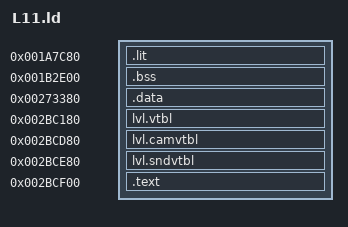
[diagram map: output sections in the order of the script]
/* GENERATED by tools/levels/gen_ld.py going-decompiled/levels/usa/L11/config/L11.yaml -- do not edit; re-run it. */
/* USA v2.00 level program 11: 7 sections at their dests, one PT_LOAD, entry 0x002BCF08,
   program sha1 36b9ba98fdfa868c2283bc5ec1bc9c0b63295a71 (archive form). Built by tools/levels/level_build.sh. */
/* From C (config/L11_c.tsv), cut out of the .text asm and linked at their place:
   func_L11_003417D0 at 0x003417D0, 0x48 bytes, src/func_L11_003417D0.c, s136 -G0
   func_L11_0036A7F8 at 0x0036A7F8, 0x110 bytes, src/func_L11_0036A7F8.c, s136 -G8
   func_L11_003983E0 at 0x003983E0, 0x130 bytes, src/func_L11_003983E0.c, s136 -G8, assembler asm_unit, extra cc1 flags -
   func_L11_003F3178 at 0x003F3178, 0xB0 bytes, src/func_L11_003F3178.c, s136 -G8, assembler asm_unit, extra cc1 flags -
   func_L11_003F4310 at 0x003F4310, 0x34 bytes, src/func_L11_003F4310.c, sdk29 -G0
   func_L11_003F4448 at 0x003F4448, 0x160 bytes, src/func_L11_003F4448.c, s136 -G8, assembler asm_unit, extra cc1 flags -
   func_L11_00414290 at 0x00414290, 0x144 bytes, src/func_L11_00414290.c, s136 -G8
   func_L11_00418AB0 at 0x00418AB0, 0x2F8 bytes, src/func_L11_00418AB0.c, s136 -G8, assembler asm_unit, extra cc1 flags -
   func_L11_00426FA0 at 0x00426FA0, 0x2C4 bytes, src/func_L11_00426FA0.c, s136 -G8, assembler asm_unit, extra cc1 flags -
   func_L11_00427310 at 0x00427310, 0xE4 bytes, src/func_L11_00427310.c, s136 -G0
   func_L11_0042B988 at 0x0042B988, 0x2C4 bytes, src/func_L11_0042B988.c, s136 -G8, assembler asm_unit, extra cc1 flags -
   func_L11_0042BCF8 at 0x0042BCF8, 0xE4 bytes, src/func_L11_0042BCF8.c, s136 -G0
   func_L11_00436338 at 0x00436338, 0x208 bytes, src/func_L11_00436338.c, s136 -G8, assembler asm_unit, extra cc1 flags -
   func_L11_00437B90 at 0x00437B90, 0x414 bytes, src/func_L11_00437B90.c, s136 -G8, assembler asm_unit, extra cc1 flags -
   func_L11_00439600 at 0x00439600, 0xA4 bytes, src/func_L11_00439600.c, s136 -G0
   func_L11_004396A8 at 0x004396A8, 0x40 bytes, src/func_L11_004396A8.c, s136 -G0
   func_L11_0043A758 at 0x0043A758, 0x1B4 bytes, src/func_L11_0043A758.c, s136 -G0
   func_L11_0043AE08 at 0x0043AE08, 0x74 bytes, src/func_L11_0043AE08.c, s136 -G8, assembler asm_unit, extra cc1 flags -
   func_L11_0043B430 at 0x0043B430, 0x16C bytes, src/func_L11_0043B430.c, s136 -G0
   func_L11_0043B5A0 at 0x0043B5A0, 0x18 bytes, src/func_L11_0043B5A0.c, s136 -G0
   func_L11_0043BC38 at 0x0043BC38, 0x228 bytes, src/func_L11_0043BC38.c, s136 -G8, assembler asm_unit, extra cc1 flags -
   func_L11_0043BE60 at 0x0043BE60, 0x5C bytes, src/func_L11_0043BE60.c, s136 -G0
   func_L11_0043C040 at 0x0043C040, 0x10 bytes, src/func_L11_0043C040.c, sdk29 -G0
   func_L11_0043C218 at 0x0043C218, 0x150 bytes, src/func_L11_0043C218.c, s136 -G8, assembler asm_unit, extra cc1 flags -
   func_L11_0043C368 at 0x0043C368, 0x188 bytes, src/func_L11_0043C368.c, s136 -G0
   func_L11_004419B0 at 0x004419B0, 0x5C bytes, src/func_L11_004419B0.c, s136 -G0
   func_L11_00441A88 at 0x00441A88, 0x128 bytes, src/func_L11_00441A88.c, sdk29 -G8
   func_L11_00441FE0 at 0x00441FE0, 0xD4 bytes, src/func_L11_00441FE0.c, s136 -G8
   func_L11_004420B8 at 0x004420B8, 0x108 bytes, src/func_L11_004420B8.c, s136 -G0
   func_L11_004424D0 at 0x004424D0, 0xC bytes, src/func_L11_004424D0.c, sdk29 -G0
   func_L11_004424E0 at 0x004424E0, 0x188 bytes, src/func_L11_004424E0.c, s136 -G0
   func_L11_00442668 at 0x00442668, 0x274 bytes, src/func_L11_00442668.c, s136 -G8, assembler asm_unit, extra cc1 flags -
   func_L11_004428E0 at 0x004428E0, 0x78 bytes, src/func_L11_004428E0.c, s136 -G0
   func_L11_00442A18 at 0x00442A18, 0x188 bytes, src/func_L11_00442A18.c, s136 -G0
   func_L11_00442FF8 at 0x00442FF8, 0x40 bytes, src/func_L11_00442FF8.c, sdk29 -G0
   func_L11_00443038 at 0x00443038, 0x20 bytes, src/func_L11_00443038.c, sdk29 -G0
   func_L11_00443058 at 0x00443058, 0x50 bytes, src/func_L11_00443058.c, sdk29 -G0
   func_L11_004430A8 at 0x004430A8, 0xC bytes, src/func_L11_004430A8.c, sdk29 -G0
   func_L11_004430B8 at 0x004430B8, 0x10C bytes, src/func_L11_004430B8.c, sdk29 -G0
   func_L11_004431C8 at 0x004431C8, 0xBC bytes, src/func_L11_004431C8.c, sdk29 -G0
   func_L11_00443C48 at 0x00443C48, 0x1D0 bytes, src/func_L11_00443C48.c, s136 -G8, assembler asm_unit, extra cc1 flags -
   func_L11_00443E18 at 0x00443E18, 0x148 bytes, src/func_L11_00443E18.c, s136 -G0
   func_L11_00443F60 at 0x00443F60, 0xA4 bytes, src/func_L11_00443F60.c, s136 -G8, assembler asm_unit, extra cc1 flags -
   func_L11_00444BD0 at 0x00444BD0, 0x58 bytes, src/func_L11_00444BD0.c, s136 -G8, assembler asm_unit, extra cc1 flags -
   func_L11_00444CE8 at 0x00444CE8, 0x4A4 bytes, src/func_L11_00444CE8.c, s136 -G8, assembler asm_unit, extra cc1 flags -
   func_L11_00447750 at 0x00447750, 0x88 bytes, src/func_L11_00447750.c, s136 -G0
   func_L11_00447A48 at 0x00447A48, 0x1A0 bytes, src/func_L11_00447A48.c, s136 -G8
   func_L11_00447BE8 at 0x00447BE8, 0x24 bytes, src/func_L11_00447BE8.c, sdk29 -G0
   func_L11_00449ED0 at 0x00449ED0, 0x39C bytes, src/func_L11_00449ED0.c, s136 -G8, assembler asm_unit, extra cc1 flags -
   func_L11_0044A270 at 0x0044A270, 0xC0 bytes, src/func_L11_0044A270.c, s136 -G0
   func_L11_0044A330 at 0x0044A330, 0x8C bytes, src/func_L11_0044A330.c, s136 -G0
   func_L11_0044A4D0 at 0x0044A4D0, 0x1D8 bytes, src/func_L11_0044A4D0.c, s136 -G8, assembler asm_unit, extra cc1 flags -
   func_L11_0044A750 at 0x0044A750, 0xD0 bytes, src/func_L11_0044A750.c, s136 -G8
   func_L11_0044AAC0 at 0x0044AAC0, 0x208 bytes, src/func_L11_0044AAC0.c, s136 -G8, assembler asm_unit, extra cc1 flags -
   func_L11_0044AD58 at 0x0044AD58, 0xC8 bytes, src/func_L11_0044AD58.c, s136 -G8, assembler asm_unit, extra cc1 flags -
   func_L11_0044D7A0 at 0x0044D7A0, 0x384 bytes, src/func_L11_0044D7A0.c, s136 -G8, assembler asm_unit, extra cc1 flags -
   func_L11_00453EA8 at 0x00453EA8, 0x3BC bytes, src/func_L11_00453EA8.c, s136 -G8, assembler asm_unit, extra cc1 flags -
   func_L11_00455F60 at 0x00455F60, 0x5D8 bytes, src/func_L11_00455F60.c, s136 -G8, assembler asm_unit, extra cc1 flags -
   func_L11_00456538 at 0x00456538, 0x80 bytes, src/func_L11_00456538.c, s136 -G0
   func_L11_004565B8 at 0x004565B8, 0x118 bytes, src/func_L11_004565B8.c, s136 -G0
   func_L11_004566D0 at 0x004566D0, 0x160 bytes, src/func_L11_004566D0.c, s136 -G0
   func_L11_00456830 at 0x00456830, 0x13C bytes, src/func_L11_00456830.c, s136 -G0
   func_L11_00457A68 at 0x00457A68, 0x5C bytes, src/func_L11_00457A68.c, s136 -G0
   func_L11_00457DD0 at 0x00457DD0, 0xC0 bytes, src/func_L11_00457DD0.c, s136 -G0
   func_L11_00457F98 at 0x00457F98, 0x94 bytes, src/func_L11_00457F98.c, s136 -G0
   func_L11_00458678 at 0x00458678, 0x280 bytes, src/func_L11_00458678.c, s136 -G0
   func_L11_0045A6F0 at 0x0045A6F0, 0xC8 bytes, src/func_L11_0045A6F0.c, s136 -G8, assembler asm_unit, extra cc1 flags -
   func_L11_0045A840 at 0x0045A840, 0x68 bytes, src/func_L11_0045A840.c, s136 -G0
   func_L11_0045AA10 at 0x0045AA10, 0x38 bytes, src/func_L11_0045AA10.c, s136 -G0
   func_L11_0045B800 at 0x0045B800, 0xFC bytes, src/func_L11_0045B800.c, s136 -G8, assembler asm_unit, extra cc1 flags -
   func_L11_00461AD8 at 0x00461AD8, 0x68 bytes, src/func_L11_00461AD8.c, s136 -G0
*/
OUTPUT_ARCH(mips)
ENTRY(func_L11_002BCF08)
PHDRS
{
    program PT_LOAD;
}
SECTIONS
{
    _gp = 0x001AEFF0;
    .lit 0x001A7C80 : { going-decompiled/build/usa_levels/L11/obj/data/lit/001A7C80.data.o(.data) } :program
    .bss 0x001B2E00 : { going-decompiled/build/usa_levels/L11/obj/data/bss/001B2E00.bss.o(.bss) } :program
    .data 0x00273380 : { going-decompiled/build/usa_levels/L11/obj/data/data/00273380.data.o(.data) } :program
    lvl.vtbl 0x002BC180 : { going-decompiled/build/usa_levels/L11/obj/data/lvl.vtbl/002BC180.data.o(.data) } :program
    lvl.camvtbl 0x002BCD80 : { going-decompiled/build/usa_levels/L11/obj/data/lvl.camvtbl/002BCD80.data.o(.data) } :program
    lvl.sndvtbl 0x002BCE80 : { going-decompiled/build/usa_levels/L11/obj/data/lvl.sndvtbl/002BCE80.data.o(.data) } :program
    .text 0x002BCF00 : {
        going-decompiled/build/usa_levels/L11/obj/text/002BCF00.cut.o(.text.cut0000)
        going-decompiled/build/usa_levels/L11/obj/c/func_L11_003417D0.o(.text)
        going-decompiled/build/usa_levels/L11/obj/text/002BCF00.cut.o(.text.cut0001)
        going-decompiled/build/usa_levels/L11/obj/c/func_L11_0036A7F8.o(.text)
        going-decompiled/build/usa_levels/L11/obj/text/002BCF00.cut.o(.text.cut0002)
        going-decompiled/build/usa_levels/L11/obj/c/func_L11_003983E0.o(.text)
        going-decompiled/build/usa_levels/L11/obj/text/002BCF00.cut.o(.text.cut0003)
        going-decompiled/build/usa_levels/L11/obj/c/func_L11_003F3178.o(.text)
        going-decompiled/build/usa_levels/L11/obj/text/002BCF00.cut.o(.text.cut0004)
        going-decompiled/build/usa_levels/L11/obj/c/func_L11_003F4310.o(.text)
        going-decompiled/build/usa_levels/L11/obj/text/002BCF00.cut.o(.text.cut0005)
        going-decompiled/build/usa_levels/L11/obj/c/func_L11_003F4448.o(.text)
        going-decompiled/build/usa_levels/L11/obj/text/002BCF00.cut.o(.text.cut0006)
        going-decompiled/build/usa_levels/L11/obj/c/func_L11_00414290.o(.text)
        going-decompiled/build/usa_levels/L11/obj/text/002BCF00.cut.o(.text.cut0007)
        going-decompiled/build/usa_levels/L11/obj/c/func_L11_00418AB0.o(.text)
        going-decompiled/build/usa_levels/L11/obj/text/002BCF00.cut.o(.text.cut0008)
        going-decompiled/build/usa_levels/L11/obj/c/func_L11_00426FA0.o(.text)
        going-decompiled/build/usa_levels/L11/obj/text/002BCF00.cut.o(.text.cut0009)
        going-decompiled/build/usa_levels/L11/obj/c/func_L11_00427310.o(.text)
        going-decompiled/build/usa_levels/L11/obj/text/002BCF00.cut.o(.text.cut0010)
        going-decompiled/build/usa_levels/L11/obj/c/func_L11_0042B988.o(.text)
        going-decompiled/build/usa_levels/L11/obj/text/002BCF00.cut.o(.text.cut0011)
        going-decompiled/build/usa_levels/L11/obj/c/func_L11_0042BCF8.o(.text)
        going-decompiled/build/usa_levels/L11/obj/text/002BCF00.cut.o(.text.cut0012)
        going-decompiled/build/usa_levels/L11/obj/c/func_L11_00436338.o(.text)
        going-decompiled/build/usa_levels/L11/obj/text/002BCF00.cut.o(.text.cut0013)
        going-decompiled/build/usa_levels/L11/obj/c/func_L11_00437B90.o(.text)
        going-decompiled/build/usa_levels/L11/obj/text/002BCF00.cut.o(.text.cut0014)
        going-decompiled/build/usa_levels/L11/obj/c/func_L11_00439600.o(.text)
        going-decompiled/build/usa_levels/L11/obj/text/002BCF00.cut.o(.text.cut0015)
        going-decompiled/build/usa_levels/L11/obj/c/func_L11_004396A8.o(.text)
        going-decompiled/build/usa_levels/L11/obj/text/002BCF00.cut.o(.text.cut0016)
        going-decompiled/build/usa_levels/L11/obj/c/func_L11_0043A758.o(.text)
        going-decompiled/build/usa_levels/L11/obj/text/002BCF00.cut.o(.text.cut0017)
        going-decompiled/build/usa_levels/L11/obj/c/func_L11_0043AE08.o(.text)
        going-decompiled/build/usa_levels/L11/obj/text/002BCF00.cut.o(.text.cut0018)
        going-decompiled/build/usa_levels/L11/obj/c/func_L11_0043B430.o(.text)
        going-decompiled/build/usa_levels/L11/obj/text/002BCF00.cut.o(.text.cut0019)
        going-decompiled/build/usa_levels/L11/obj/c/func_L11_0043B5A0.o(.text)
        going-decompiled/build/usa_levels/L11/obj/text/002BCF00.cut.o(.text.cut0020)
        going-decompiled/build/usa_levels/L11/obj/c/func_L11_0043BC38.o(.text)
        going-decompiled/build/usa_levels/L11/obj/text/002BCF00.cut.o(.text.cut0021)
        going-decompiled/build/usa_levels/L11/obj/c/func_L11_0043BE60.o(.text)
        going-decompiled/build/usa_levels/L11/obj/text/002BCF00.cut.o(.text.cut0022)
        going-decompiled/build/usa_levels/L11/obj/c/func_L11_0043C040.o(.text)
        going-decompiled/build/usa_levels/L11/obj/text/002BCF00.cut.o(.text.cut0023)
        going-decompiled/build/usa_levels/L11/obj/c/func_L11_0043C218.o(.text)
        going-decompiled/build/usa_levels/L11/obj/text/002BCF00.cut.o(.text.cut0024)
        going-decompiled/build/usa_levels/L11/obj/c/func_L11_0043C368.o(.text)
        going-decompiled/build/usa_levels/L11/obj/text/002BCF00.cut.o(.text.cut0025)
        going-decompiled/build/usa_levels/L11/obj/c/func_L11_004419B0.o(.text)
        going-decompiled/build/usa_levels/L11/obj/text/002BCF00.cut.o(.text.cut0026)
        going-decompiled/build/usa_levels/L11/obj/c/func_L11_00441A88.o(.text)
        going-decompiled/build/usa_levels/L11/obj/text/002BCF00.cut.o(.text.cut0027)
        going-decompiled/build/usa_levels/L11/obj/c/func_L11_00441FE0.o(.text)
        going-decompiled/build/usa_levels/L11/obj/text/002BCF00.cut.o(.text.cut0028)
        going-decompiled/build/usa_levels/L11/obj/c/func_L11_004420B8.o(.text)
        going-decompiled/build/usa_levels/L11/obj/text/002BCF00.cut.o(.text.cut0029)
        going-decompiled/build/usa_levels/L11/obj/c/func_L11_004424D0.o(.text)
        going-decompiled/build/usa_levels/L11/obj/text/002BCF00.cut.o(.text.cut0030)
        going-decompiled/build/usa_levels/L11/obj/c/func_L11_004424E0.o(.text)
        going-decompiled/build/usa_levels/L11/obj/text/002BCF00.cut.o(.text.cut0031)
        going-decompiled/build/usa_levels/L11/obj/c/func_L11_00442668.o(.text)
        going-decompiled/build/usa_levels/L11/obj/text/002BCF00.cut.o(.text.cut0032)
        going-decompiled/build/usa_levels/L11/obj/c/func_L11_004428E0.o(.text)
        going-decompiled/build/usa_levels/L11/obj/text/002BCF00.cut.o(.text.cut0033)
        going-decompiled/build/usa_levels/L11/obj/c/func_L11_00442A18.o(.text)
        going-decompiled/build/usa_levels/L11/obj/text/002BCF00.cut.o(.text.cut0034)
        going-decompiled/build/usa_levels/L11/obj/c/func_L11_00442FF8.o(.text)
        going-decompiled/build/usa_levels/L11/obj/text/002BCF00.cut.o(.text.cut0035)
        going-decompiled/build/usa_levels/L11/obj/c/func_L11_00443038.o(.text)
        going-decompiled/build/usa_levels/L11/obj/text/002BCF00.cut.o(.text.cut0036)
        going-decompiled/build/usa_levels/L11/obj/c/func_L11_00443058.o(.text)
        going-decompiled/build/usa_levels/L11/obj/text/002BCF00.cut.o(.text.cut0037)
        going-decompiled/build/usa_levels/L11/obj/c/func_L11_004430A8.o(.text)
        going-decompiled/build/usa_levels/L11/obj/text/002BCF00.cut.o(.text.cut0038)
        going-decompiled/build/usa_levels/L11/obj/c/func_L11_004430B8.o(.text)
        going-decompiled/build/usa_levels/L11/obj/text/002BCF00.cut.o(.text.cut0039)
        going-decompiled/build/usa_levels/L11/obj/c/func_L11_004431C8.o(.text)
        going-decompiled/build/usa_levels/L11/obj/text/002BCF00.cut.o(.text.cut0040)
        going-decompiled/build/usa_levels/L11/obj/c/func_L11_00443C48.o(.text)
        going-decompiled/build/usa_levels/L11/obj/text/002BCF00.cut.o(.text.cut0041)
        going-decompiled/build/usa_levels/L11/obj/c/func_L11_00443E18.o(.text)
        going-decompiled/build/usa_levels/L11/obj/text/002BCF00.cut.o(.text.cut0042)
        going-decompiled/build/usa_levels/L11/obj/c/func_L11_00443F60.o(.text)
        going-decompiled/build/usa_levels/L11/obj/text/002BCF00.cut.o(.text.cut0043)
        going-decompiled/build/usa_levels/L11/obj/c/func_L11_00444BD0.o(.text)
        going-decompiled/build/usa_levels/L11/obj/text/002BCF00.cut.o(.text.cut0044)
        going-decompiled/build/usa_levels/L11/obj/c/func_L11_00444CE8.o(.text)
        going-decompiled/build/usa_levels/L11/obj/text/002BCF00.cut.o(.text.cut0045)
        going-decompiled/build/usa_levels/L11/obj/c/func_L11_00447750.o(.text)
        going-decompiled/build/usa_levels/L11/obj/text/002BCF00.cut.o(.text.cut0046)
        going-decompiled/build/usa_levels/L11/obj/c/func_L11_00447A48.o(.text)
        going-decompiled/build/usa_levels/L11/obj/text/002BCF00.cut.o(.text.cut0047)
        going-decompiled/build/usa_levels/L11/obj/c/func_L11_00447BE8.o(.text)
        going-decompiled/build/usa_levels/L11/obj/text/002BCF00.cut.o(.text.cut0048)
        going-decompiled/build/usa_levels/L11/obj/c/func_L11_00449ED0.o(.text)
        going-decompiled/build/usa_levels/L11/obj/text/002BCF00.cut.o(.text.cut0049)
        going-decompiled/build/usa_levels/L11/obj/c/func_L11_0044A270.o(.text)
        going-decompiled/build/usa_levels/L11/obj/text/002BCF00.cut.o(.text.cut0050)
        going-decompiled/build/usa_levels/L11/obj/c/func_L11_0044A330.o(.text)
        going-decompiled/build/usa_levels/L11/obj/text/002BCF00.cut.o(.text.cut0051)
        going-decompiled/build/usa_levels/L11/obj/c/func_L11_0044A4D0.o(.text)
        going-decompiled/build/usa_levels/L11/obj/text/002BCF00.cut.o(.text.cut0052)
        going-decompiled/build/usa_levels/L11/obj/c/func_L11_0044A750.o(.text)
        going-decompiled/build/usa_levels/L11/obj/text/002BCF00.cut.o(.text.cut0053)
        going-decompiled/build/usa_levels/L11/obj/c/func_L11_0044AAC0.o(.text)
        going-decompiled/build/usa_levels/L11/obj/text/002BCF00.cut.o(.text.cut0054)
        going-decompiled/build/usa_levels/L11/obj/c/func_L11_0044AD58.o(.text)
        going-decompiled/build/usa_levels/L11/obj/text/002BCF00.cut.o(.text.cut0055)
        going-decompiled/build/usa_levels/L11/obj/c/func_L11_0044D7A0.o(.text)
        going-decompiled/build/usa_levels/L11/obj/text/002BCF00.cut.o(.text.cut0056)
        going-decompiled/build/usa_levels/L11/obj/c/func_L11_00453EA8.o(.text)
        going-decompiled/build/usa_levels/L11/obj/text/002BCF00.cut.o(.text.cut0057)
        going-decompiled/build/usa_levels/L11/obj/c/func_L11_00455F60.o(.text)
        going-decompiled/build/usa_levels/L11/obj/text/002BCF00.cut.o(.text.cut0058)
        going-decompiled/build/usa_levels/L11/obj/c/func_L11_00456538.o(.text)
        going-decompiled/build/usa_levels/L11/obj/text/002BCF00.cut.o(.text.cut0059)
        going-decompiled/build/usa_levels/L11/obj/c/func_L11_004565B8.o(.text)
        going-decompiled/build/usa_levels/L11/obj/text/002BCF00.cut.o(.text.cut0060)
        going-decompiled/build/usa_levels/L11/obj/c/func_L11_004566D0.o(.text)
        going-decompiled/build/usa_levels/L11/obj/text/002BCF00.cut.o(.text.cut0061)
        going-decompiled/build/usa_levels/L11/obj/c/func_L11_00456830.o(.text)
        going-decompiled/build/usa_levels/L11/obj/text/002BCF00.cut.o(.text.cut0062)
        going-decompiled/build/usa_levels/L11/obj/c/func_L11_00457A68.o(.text)
        going-decompiled/build/usa_levels/L11/obj/text/002BCF00.cut.o(.text.cut0063)
        going-decompiled/build/usa_levels/L11/obj/c/func_L11_00457DD0.o(.text)
        going-decompiled/build/usa_levels/L11/obj/text/002BCF00.cut.o(.text.cut0064)
        going-decompiled/build/usa_levels/L11/obj/c/func_L11_00457F98.o(.text)
        going-decompiled/build/usa_levels/L11/obj/text/002BCF00.cut.o(.text.cut0065)
        going-decompiled/build/usa_levels/L11/obj/c/func_L11_00458678.o(.text)
        going-decompiled/build/usa_levels/L11/obj/text/002BCF00.cut.o(.text.cut0066)
        going-decompiled/build/usa_levels/L11/obj/c/func_L11_0045A6F0.o(.text)
        going-decompiled/build/usa_levels/L11/obj/text/002BCF00.cut.o(.text.cut0067)
        going-decompiled/build/usa_levels/L11/obj/c/func_L11_0045A840.o(.text)
        going-decompiled/build/usa_levels/L11/obj/text/002BCF00.cut.o(.text.cut0068)
        going-decompiled/build/usa_levels/L11/obj/c/func_L11_0045AA10.o(.text)
        going-decompiled/build/usa_levels/L11/obj/text/002BCF00.cut.o(.text.cut0069)
        going-decompiled/build/usa_levels/L11/obj/c/func_L11_0045B800.o(.text)
        going-decompiled/build/usa_levels/L11/obj/text/002BCF00.cut.o(.text.cut0070)
        going-decompiled/build/usa_levels/L11/obj/c/func_L11_00461AD8.o(.text)
        going-decompiled/build/usa_levels/L11/obj/text/002BCF00.cut.o(.text.cut0071)
    } :program
    /DISCARD/ : { *(*) }
}

/* The resident core below 0x001A7C80: the boot's names, as absolute values
   (symbol_addrs/core_externs.txt, 536 entries). */
memcmp = ABSOLUTE(0x00115340);
memcpy = ABSOLUTE(0x001153D4);
memset = ABSOLUTE(0x00115484);
func_0011B580 = ABSOLUTE(0x0011B580);
func_0011B588 = ABSOLUTE(0x0011B588);
func_0011BB30 = ABSOLUTE(0x0011BB30);
HandleRpcBindRequest = ABSOLUTE(0x0011D3A0);
isnan = ABSOLUTE(0x001313C8);
e_sqrt = ABSOLUTE(0x001310C0);
sqrt = ABSOLUTE(0x00131430);
__fdlib_version = ABSOLUTE(0x0013BF10);
func_0011E740 = ABSOLUTE(0x0011E740);
func_00115E68 = ABSOLUTE(0x00115E68);
sceSifInitIopHeap = ABSOLUTE(0x0011E7A0);
sceCdRead = ABSOLUTE(0x001253A8);
func_00127218 = ABSOLUTE(0x00127218);
func_00127220 = ABSOLUTE(0x00127220);
func_00128A48 = ABSOLUTE(0x00128A48);
func_00128A50 = ABSOLUTE(0x00128A50);
func_0012EB28 = ABSOLUTE(0x0012EB28);
func_0012EB30 = ABSOLUTE(0x0012EB30);
func_0012F948 = ABSOLUTE(0x0012F948);
func_0012F950 = ABSOLUTE(0x0012F950);
func_00131620 = ABSOLUTE(0x00131620);
func_00131628 = ABSOLUTE(0x00131628);
func_00132818 = ABSOLUTE(0x00132818);
func_00132828 = ABSOLUTE(0x00132828);
func_00132968 = ABSOLUTE(0x00132968);
func_00132978 = ABSOLUTE(0x00132978);
func_001329F0 = ABSOLUTE(0x001329F0);
func_00132A10 = ABSOLUTE(0x00132A10);
func_00132A58 = ABSOLUTE(0x00132A58);
func_00132A70 = ABSOLUTE(0x00132A70);
func_00132AA0 = ABSOLUTE(0x00132AA0);
func_00132AC8 = ABSOLUTE(0x00132AC8);
func_00132B88 = ABSOLUTE(0x00132B88);
func_00132BC0 = ABSOLUTE(0x00132BC0);
func_00133300 = ABSOLUTE(0x00133300);
func_00133310 = ABSOLUTE(0x00133310);
func_00133340 = ABSOLUTE(0x00133340);
snd_PlaySample = ABSOLUTE(0x00133350);
func_001333C0 = ABSOLUTE(0x001333C0);
func_001333D0 = ABSOLUTE(0x001333D0);
func_001336C0 = ABSOLUTE(0x001336C0);
SetSndPumpCallback = ABSOLUTE(0x001336D0);
func_00133700 = ABSOLUTE(0x00133700);
func_00133710 = ABSOLUTE(0x00133710);
func_001337C8 = ABSOLUTE(0x001337C8);
func_001337F0 = ABSOLUTE(0x001337F0);
func_00133818 = ABSOLUTE(0x00133818);
func_00133820 = ABSOLUTE(0x00133820);
func_00133848 = ABSOLUTE(0x00133848);
func_00133850 = ABSOLUTE(0x00133850);
func_001338B8 = ABSOLUTE(0x001338B8);
func_001338C8 = ABSOLUTE(0x001338C8);
func_00133928 = ABSOLUTE(0x00133928);
func_00133930 = ABSOLUTE(0x00133930);
func_00115228 = ABSOLUTE(0x00115228);
func_001158F8 = ABSOLUTE(0x001158F8);
func_00124418 = ABSOLUTE(0x00124418);
func_00125D98 = ABSOLUTE(0x00125D98);
func_00126108 = ABSOLUTE(0x00126108);
func_00126288 = ABSOLUTE(0x00126288);
func_00126470 = ABSOLUTE(0x00126470);
func_00126730 = ABSOLUTE(0x00126730);
func_00126DC0 = ABSOLUTE(0x00126DC0);
func_00128F50 = ABSOLUTE(0x00128F50);
func_001290E0 = ABSOLUTE(0x001290E0);
func_0011F9E8 = ABSOLUTE(0x0011F9E8);
func_00129120 = ABSOLUTE(0x00129120);
func_00129148 = ABSOLUTE(0x00129148);
func_00129160 = ABSOLUTE(0x00129160);
func_00129178 = ABSOLUTE(0x00129178);
func_0012F998 = ABSOLUTE(0x0012F998);
func_0012F9A8 = ABSOLUTE(0x0012F9A8);
func_0011B8D8 = ABSOLUTE(0x0011B8D8);
func_0011DE08 = ABSOLUTE(0x0011DE08);
func_0011D9C0 = ABSOLUTE(0x0011D9C0);
func_0011DDD8 = ABSOLUTE(0x0011DDD8);
func_00129DA8 = ABSOLUTE(0x00129DA8);
func_0011A900 = ABSOLUTE(0x0011A900);
func_0011B5F0 = ABSOLUTE(0x0011B5F0);
func_001246D0 = ABSOLUTE(0x001246D0);
func_001246E0 = ABSOLUTE(0x001246E0);
func_00124630 = ABSOLUTE(0x00124630);
func_0012E238 = ABSOLUTE(0x0012E238);
func_001248B0 = ABSOLUTE(0x001248B0);
func_001248B8 = ABSOLUTE(0x001248B8);
func_00130A8C = ABSOLUTE(0x00130A8C);
func_00130A90 = ABSOLUTE(0x00130A90);
IpuDecodePictureData = ABSOLUTE(0x0012B678);
IpuMotionCompensation = ABSOLUTE(0x00129450);
IpuDecodeMacroblock = ABSOLUTE(0x0012BB60);
ParsePesPacketHeader = ABSOLUTE(0x0012F0E0);
func_0012B0D8 = ABSOLUTE(0x0012B0D8);
func_00130428 = ABSOLUTE(0x00130428);
func_0011A940 = ABSOLUTE(0x0011A940);
func_0012E378 = ABSOLUTE(0x0012E378);
func_0012E538 = ABSOLUTE(0x0012E538);
sceIpuRestartDMA = ABSOLUTE(0x00130C68);
sceIpuStopDMA = ABSOLUTE(0x00130B80);
_sysbitFlush = ABSOLUTE(0x0012E8E8);
func_0011BCD0 = ABSOLUTE(0x0011BCD0);
func_0012EAA0 = ABSOLUTE(0x0012EAA0);
func_0012D808 = ABSOLUTE(0x0012D808);
func_0012DAC0 = ABSOLUTE(0x0012DAC0);
func_0012E608 = ABSOLUTE(0x0012E608);
func_0012FD60 = ABSOLUTE(0x0012FD60);
func_0012FEC0 = ABSOLUTE(0x0012FEC0);
func_00124980 = ABSOLUTE(0x00124980);
func_0012C680 = ABSOLUTE(0x0012C680);
func_0012DC50 = ABSOLUTE(0x0012DC50);
func_0012DD60 = ABSOLUTE(0x0012DD60);
g_boltCount = ABSOLUTE(0x001A7A00);
g_raritanium = ABSOLUTE(0x001A7A04);
g_miscExtras = ABSOLUTE(0x001A7A12);
g_nanotech = ABSOLUTE(0x001A7A14);
g_equippedArmor = ABSOLUTE(0x001A7A20);
g_crystals = ABSOLUTE(0x001A7A22);
g_moonstones = ABSOLUTE(0x001A7A24);
g_health = ABSOLUTE(0x0018C2EC);
g_maxHealth = ABSOLUTE(0x001A7A08);
g_air = ABSOLUTE(0x0018C2E0);
g_giantClankHealth = ABSOLUTE(0x0018B694);
g_playerProgress = ABSOLUTE(0x001A79F8);
g_saveImageGlobal = ABSOLUTE(0x001A2BA8);
g_saveImageArea = ABSOLUTE(0x001A53A8);
g_saveSlotInfoTable = ABSOLUTE(0x00139410);
snd_BankLoadByLoc = ABSOLUTE(0x00132318);
snd_BankLoadFromIOP = ABSOLUTE(0x001326D8);
snd_BankLoadFromEE_CB = ABSOLUTE(0x001325E8);
snd_Init = ABSOLUTE(0x00131DE8);
snd_BankLoadAsync = ABSOLUTE(0x00132498);
snd_ServiceRpcCompletion = ABSOLUTE(0x00132220);
snd_SendCommandSync = ABSOLUTE(0x00132C48);
snd_QueueCommandToRing = ABSOLUTE(0x00132DF0);
snd_FlushCommandRing = ABSOLUTE(0x00133108);
snd_Pump = ABSOLUTE(0x00132028);
snd_SetupDmaTransfer = ABSOLUTE(0x001322B8);
snd_CommitRingEntry = ABSOLUTE(0x001330D0);
snd_CheckLoadInProgress = ABSOLUTE(0x00133580);
snd_PrintError = ABSOLUTE(0x00115D48);
AssertFail = ABSOLUTE(0x00115E38);
g_mapDataSet = ABSOLUTE(0x001A7B05);
g_mapRevealedFlags = ABSOLUTE(0x0013965F);
g_mcPendingCmd = ABSOLUTE(0x00137E68);
g_mcMutexSema = ABSOLUTE(0x00137E6C);
g_mcInitialized = ABSOLUTE(0x00141B24);
g_mcRpcClient = ABSOLUTE(0x00141B00);
g_mcRpcResult = ABSOLUTE(0x001430C0);
g_mcRpcPathRequest = ABSOLUTE(0x00141BB0);
McInit = ABSOLUTE(0x00127348);
McSync = ABSOLUTE(0x00127B88);
McGetInfo = ABSOLUTE(0x00127CC0);
McOpen = ABSOLUTE(0x00127508);
McClose = ABSOLUTE(0x00127668);
McSeek = ABSOLUTE(0x00127720);
McRead = ABSOLUTE(0x00127888);
McWrite = ABSOLUTE(0x001279A0);
McGetDir = ABSOLUTE(0x00127E48);
McMkDir = ABSOLUTE(0x00128068);
McBeginCreateFile = ABSOLUTE(0x00127630);
McDelayMillis = ABSOLUTE(0x00127B40);
McChdir = ABSOLUTE(0x00127F98);
McGetEntSpace = ABSOLUTE(0x00128180);
g_saveDirTemplate = ABSOLUTE(0x001A7938);
g_saveIconSysPath = ABSOLUTE(0x001A7968);
g_saveStaticIcoPath = ABSOLUTE(0x001A7988);
g_saveFileFmt = ABSOLUTE(0x001A79D8);
g_cinematicUnlockedFlags = ABSOLUTE(0x00139768);
g_bonusUnlockFlags = ABSOLUTE(0x00139780);
g_weaponUpgradeLevel = ABSOLUTE(0x00139A34);
g_mapBlipTable = ABSOLUTE(0x00139A28);
g_saveClock = ABSOLUTE(0x001A7360);
g_platinumBoltFlags = ABSOLUTE(0x0019B278);
g_cheatFlags = ABSOLUTE(0x001A7A48);
g_skillPointFlags = ABSOLUTE(0x001A7A68);
g_itemEquippedSlot = ABSOLUTE(0x00139568);
g_weaponAmmo = ABSOLUTE(0x00139688);
g_weaponXp = ABSOLUTE(0x00139868);
g_inventoryOwned = ABSOLUTE(0x001A7B00);
g_inventoryNewFlag = ABSOLUTE(0x001A7B38);
g_inventoryOrder = ABSOLUTE(0x001A7B70);
g_equippedItemSlots = ABSOLUTE(0x001A73B8);
g_activeGadgetItem = ABSOLUTE(0x0018C0E8);
g_gadgetClassToc = ABSOLUTE(0x00150080);
g_residentGadgetClassCache = ABSOLUTE(0x00152D04);
g_gadgetClassSramBase = ABSOLUTE(0x00152D10);
g_padButtonsHeld = ABSOLUTE(0x00138340);
g_padButtonsPressed = ABSOLUTE(0x00138344);
g_bPlayerMode = ABSOLUTE(0x0018C0D4);
g_nNanotechBonusHealTimer = ABSOLUTE(0x00189FFC);
g_bNanotechBonusHealEnabled = ABSOLUTE(0x001A7A4E);
g_currentLanguage = ABSOLUTE(0x001A7BBC);
g_abLevelAvailableFlags = ABSOLUTE(0x001A7BD0);
g_anAvailableLevelOrder = ABSOLUTE(0x00139948);
g_nSavePromptPending = ABSOLUTE(0x001A7B94);
g_nSaveLoadStatusCode = ABSOLUTE(0x001A7420);
g_dialogVoiceActive = ABSOLUTE(0x001A6410);
g_dialogVoiceId = ABSOLUTE(0x001A6414);
g_dialogVoicePhase = ABSOLUTE(0x001A641A);
g_pendingDialogVoiceId = ABSOLUTE(0x001A63CC);
CdStartRead = ABSOLUTE(0x001334B8);
CdStopRead = ABSOLUTE(0x00133640);
CdGetLoadStatus = ABSOLUTE(0x00133688);
CdReadSync = ABSOLUTE(0x00133A28);
LoadDiscToc = ABSOLUTE(0x00133A78);
LoadLevelToc = ABSOLUTE(0x00133AA0);
g_fileLoadVoiceState = ABSOLUTE(0x001A63A8);
g_fileLoadState = ABSOLUTE(0x001A63AC);
g_bFileLoadAborted = ABSOLUTE(0x001A63AE);
g_fileLoadLbn = ABSOLUTE(0x001A63B0);
g_fileLoadSectorCount = ABSOLUTE(0x001A63B8);
g_fileLoadDest = ABSOLUTE(0x001A63BC);
g_fileLoadCallback = ABSOLUTE(0x001A63C0);
g_fileLoadCallbackArg = ABSOLUTE(0x001A63C4);
g_cdReadMode = ABSOLUTE(0x001A63E8);
g_discToc = ABSOLUTE(0x0014B540);
g_levelWadBaseLbn = ABSOLUTE(0x0014B86C);
g_globalWadBaseLbn = ABSOLUTE(0x0014B8AC);
g_mapDataTocPrimary = ABSOLUTE(0x0014CA30);
g_mapDataTocSecondary = ABSOLUTE(0x0014CB10);
g_textTableLbnOffset = ABSOLUTE(0x0014CBF0);
g_levelTocDirectory = ABSOLUTE(0x00150538);
g_levelTocHeader = ABSOLUTE(0x001507D8);
g_levelAssetToc = ABSOLUTE(0x00150838);
g_levelDialogToc = ABSOLUTE(0x00151850);
g_sndIopLoadStatus = ABSOLUTE(0x001A7110);
g_sndIopReady = ABSOLUTE(0x001A748C);
g_soundEmitterTable = ABSOLUTE(0x001886D0);
g_listenerPosHistory = ABSOLUTE(0x00188660);
g_listenerPosHistoryIdx = ABSOLUTE(0x001886A0);
g_soundBankHandles = ABSOLUTE(0x00189E00);
g_listenerOcclusionProbes = ABSOLUTE(0x00189DA0);
g_sndChannelVolumes = ABSOLUTE(0x001886A8);
g_musicVolume = ABSOLUTE(0x001A7BA8);
g_sfxVolume = ABSOLUTE(0x001A7BA4);
g_audioStereoMode = ABSOLUTE(0x001A7BA0);
g_heroPos = ABSOLUTE(0x00189EA0);
QueryCdStatusOverRpc = ABSOLUTE(0x00125588);
g_levelStagingState = ABSOLUTE(0x001A7280);
g_bLoadingSceneBanksHeld = ABSOLUTE(0x001A7284);
g_pLoadedSegment = ABSOLUTE(0x001A7288);
g_pStagedChunkB = ABSOLUTE(0x001A728C);
g_rawReadStallTimer = ABSOLUTE(0x001A7430);
g_bRawReadFellBack = ABSOLUTE(0x001A7434);
g_rawReadSpindleCtrl = ABSOLUTE(0x001A7900);
g_levelVisitedMarkers = ABSOLUTE(0x001A7BF0);
g_exitSceneMode = ABSOLUTE(0x00152C20);
g_scenePlayerFadedOut = ABSOLUTE(0x00152C2C);
g_loadingSceneVariant = ABSOLUTE(0x00152C2E);
g_shipTakeoffSplineIndex = ABSOLUTE(0x00152C40);
g_loadingSceneIndex = ABSOLUTE(0x00152C64);
g_loadingScenesPlayed = ABSOLUTE(0x00152C68);
g_sceneWadBaseLbn = ABSOLUTE(0x0014F364);
g_globalSceneToc = ABSOLUTE(0x0014F368);
g_loadingSceneWadToc = ABSOLUTE(0x0014F398);
g_menuBgImageTocA = ABSOLUTE(0x0014C310);
g_menuBgImageTocB = ABSOLUTE(0x0014C338);
g_pHeroMoby = ABSOLUTE(0x0018C0B0);
g_heroState = ABSOLUTE(0x0018C0B4);
g_heroFacingDir = ABSOLUTE(0x0018A0E0);
g_cameraZoneType = ABSOLUTE(0x0018C2C0);
rand = ABSOLUTE(0x001163B0);
srand = ABSOLUTE(0x001163A0);
strstr = ABSOLUTE(0x001163E0);
g_vblankCount = ABSOLUTE(0x001A7208);
g_hblankTicksAccum = ABSOLUTE(0x001A7200);
g_bPalMode = ABSOLUTE(0x001A7B98);
g_bProgressiveScan = ABSOLUTE(0x001A7BC0);
g_loadedArmorVariant = ABSOLUTE(0x001A7290);
g_pPlayerModelBuffer = ABSOLUTE(0x001A7294);
g_playerTexCount = ABSOLUTE(0x001A7298);
g_playerTexDescriptors = ABSOLUTE(0x001A72A0);
g_loadedHeldItemModelId = ABSOLUTE(0x001A72C0);
g_heldItemTexDescriptor = ABSOLUTE(0x001A72C8);
g_loadedShipModelVariant = ABSOLUTE(0x00152C18);
g_loadedShipTextureIndex = ABSOLUTE(0x00152C30);
g_shipTexDescriptor = ABSOLUTE(0x00152C38);
g_shipModelToc = ABSOLUTE(0x0014FE18);
g_shipTextureToc = ABSOLUTE(0x0014FE30);
g_castModelWadBaseLbn = ABSOLUTE(0x00150444);
g_castModelToc = ABSOLUTE(0x00150448);
g_shipCustomization = ABSOLUTE(0x001A7AF8);
_start = ABSOLUTE(0x00131AE8);
main = ABSOLUTE(0x00131D98);
InstallLoadedOverlay = ABSOLUTE(0x00131CB8);
_InitSys = ABSOLUTE(0x0011F828);
exit = ABSOLUTE(0x0011FA20);
sceSifRebootIop = ABSOLUTE(0x0011EED8);
sceSifResetIop = ABSOLUTE(0x0011ED60);
sceSifInitRpc = ABSOLUTE(0x0011CF78);
sceSifFreeSysMemory = ABSOLUTE(0x0011E8A8);
sceSifBindRpc = ABSOLUTE(0x0011D450);
sceSifCallRpc = ABSOLUTE(0x0011D620);
sceSifCheckStatRpc = ABSOLUTE(0x0011D810);
sceSifWriteBackDCache = ABSOLUTE(0x0011CEC8);
strncpy = ABSOLUTE(0x00115AC0);
strcmp = ABSOLUTE(0x00115544);
strcpy = ABSOLUTE(0x00115690);
strlen = ABSOLUTE(0x001157AC);
malloc = ABSOLUTE(0x00115F28);
abort = ABSOLUTE(0x00115E28);
exit_runAtexitHandlers = ABSOLUTE(0x00115E90);
_exitThunk = ABSOLUTE(0x00131CA8);
Kprintf = ABSOLUTE(0x0011C820);
sceCdInit = ABSOLUTE(0x00124E08);
sceCdDiskReady = ABSOLUTE(0x001250E8);
sceCdMmode = ABSOLUTE(0x001252E0);
sceCdReadClock = ABSOLUTE(0x001256D8);
sceGsResetGraph = ABSOLUTE(0x001257D0);
sceDbcInit = ABSOLUTE(0x001282A8);
sceDbcPortOpen = ABSOLUTE(0x00128900);
OnVblankInterrupt = ABSOLUTE(0x001339B0);
WaitVblankStartIntc = ABSOLUTE(0x0011B0B0);
WaitVblankGetField = ABSOLUTE(0x001261F0);
WaitGsPathsIdle = ABSOLUTE(0x001244B8);
ResetDmacChannels = ABSOLUTE(0x00126F60);
sceDmaPutEnv = ABSOLUTE(0x00127040);
KickGifImageUpload = ABSOLUTE(0x001265B0);
sceDmaSyncChan = ABSOLUTE(0x00126E60);
BuildGsDispEnv = ABSOLUTE(0x00125A20);
BuildGsDrawEnvPacket = ABSOLUTE(0x00125F20);
GsDefDispEnvNeedsOffsetFix = ABSOLUTE(0x00125970);
GetGsDisplayOffsets = ABSOLUTE(0x00125A10);
CalcGsZbufferBasePtr = ABSOLUTE(0x00125E58);
DisableDmac = ABSOLUTE(0x0011B658);
EnableDmac = ABSOLUTE(0x0011B6C0);
g_vramAllocCursor = ABSOLUTE(0x001A72D0);
g_vramDynamicBase = ABSOLUTE(0x001A72D4);
g_vramFrameBufA = ABSOLUTE(0x001A72D8);
g_vramFrameBufB = ABSOLUTE(0x001A72DC);
g_vramZBuffer = ABSOLUTE(0x001A72E0);
g_vramTextureBase = ABSOLUTE(0x001A72E4);
g_gsScreenContext = ABSOLUTE(0x001A6480);
g_gsScreenContextPtr = ABSOLUTE(0x001A742C);
g_screenClearPacketA = ABSOLUTE(0x001A6D40);
g_screenClearPacketB = ABSOLUTE(0x001A6E90);
g_screenBlitPacketA = ABSOLUTE(0x001A6600);
g_screenBlitPacketB = ABSOLUTE(0x001A6860);
g_fullScreenTintPacket = ABSOLUTE(0x00138850);
g_fadeQuadPacket = ABSOLUTE(0x00138990);
g_screenWidth = ABSOLUTE(0x001A7340);
g_screenHeight = ABSOLUTE(0x001A7344);
g_gsPixelOffsetX = ABSOLUTE(0x001A7350);
g_gsPixelOffsetY = ABSOLUTE(0x001A7354);
g_respawnReturnTransform = ABSOLUTE(0x00152C70);
g_respawnPlayerPos = ABSOLUTE(0x00152C80);
g_respawnPlayerYaw = ABSOLUTE(0x00152C88);
g_bGlobalSceneActive = ABSOLUTE(0x0018C0D5);
g_pendingBoltCredit = ABSOLUTE(0x001A7A1C);
g_pendingNanotechXp = ABSOLUTE(0x001A7A18);
g_itemStateFlags = ABSOLUTE(0x001A7A88);
D_1A7318 = ABSOLUTE(0x001A7318);
g_bestiaryKillCounts = ABSOLUTE(0x00188510);
g_itemEquipSlotTable = ABSOLUTE(0x001A7398);
g_areaTable = ABSOLUTE(0x001393E0);
g_cinematicExitPending = ABSOLUTE(0x001A7478);
g_exitSceneArmed = ABSOLUTE(0x0013955C);
g_cinematicCameraBlock = ABSOLUTE(0x0018B2F0);
g_heroOrientVec = ABSOLUTE(0x00189EB0);
g_heroPos_D0 = ABSOLUTE(0x00189F70);
g_pendingVoiceAux = ABSOLUTE(0x001A63D0);
g_mobyClassTable = ABSOLUTE(0x0018B040);
g_quickSelectMap = ABSOLUTE(0x00139587);
g_vramTextureBase_28 = ABSOLUTE(0x001A730C);
g_bRawReadFellBack_34 = ABSOLUTE(0x001A7468);
g_screenCenterDefaultX = ABSOLUTE(0x001A7348);
g_screenCenterDefaultY = ABSOLUTE(0x001A734C);
g_soundBankHandlesBlk = ABSOLUTE(0x00189E20);
__divdi3 = ABSOLUTE(0x0011FC68);
__moddi3 = ABSOLUTE(0x00121450);
__muldi3 = ABSOLUTE(0x00121AB8);
__udivdi3 = ABSOLUTE(0x00121B20);
__umoddi3 = ABSOLUTE(0x001220F0);
new_eh_context = ABSOLUTE(0x001203C8);
eh_context_static = ABSOLUTE(0x00120498);
__sjthrow = ABSOLUTE(0x00120528);
old_find_exception_handler = ABSOLUTE(0x00120810);
find_exception_handler = ABSOLUTE(0x001208E8);
get_reg_addr = ABSOLUTE(0x00120A30);
copy_reg = ABSOLUTE(0x00120AB8);
next_stack_level = ABSOLUTE(0x00120B38);
throw_helper = ABSOLUTE(0x00120BD0);
__throw = ABSOLUTE(0x00120F00);
__rethrow = ABSOLUTE(0x001210E0);
__fixunsdfdi = ABSOLUTE(0x001212C8);
__floatdidf = ABSOLUTE(0x001213B8);
__pack_d = ABSOLUTE(0x00122630);
__unpack_d = ABSOLUTE(0x00122760);
_fpadd_parts = ABSOLUTE(0x00122800);
dpadd = ABSOLUTE(0x00122A40);
dpsub = ABSOLUTE(0x00122A98);
dpmul = ABSOLUTE(0x00122B00);
dpdiv = ABSOLUTE(0x00122DA8);
dpcmp = ABSOLUTE(0x00123028);
litodp = ABSOLUTE(0x00123078);
dptofp = ABSOLUTE(0x00123298);
__pack_f = ABSOLUTE(0x001232F0);
__unpack_f = ABSOLUTE(0x00123400);
decode_uleb128 = ABSOLUTE(0x00123530);
decode_sleb128 = ABSOLUTE(0x00123578);
fde_merge = ABSOLUTE(0x001235C8);
end_fde_sort = ABSOLUTE(0x001236C8);
count_fdes = ABSOLUTE(0x00123930);
add_fdes = ABSOLUTE(0x00123978);
frame_init = ABSOLUTE(0x00123A00);
find_fde = ABSOLUTE(0x00123B40);
extract_cie_info = ABSOLUTE(0x00123C28);
execute_cfa_insn = ABSOLUTE(0x00123D30);
__frame_state_for = ABSOLUTE(0x001240C8);
fde_split = ABSOLUTE(0x001242A0);
func_00122F10 = ABSOLUTE(0x00122F10);
func_00123268 = ABSOLUTE(0x00123268);
g_sndRpcClientCmd = ABSOLUTE(0x001A7040);
g_sndCmdRpcSend = ABSOLUTE(0x001A70C0);
g_sndCmdRpcRecv = ABSOLUTE(0x001A7080);
g_sndRpcClientBank = ABSOLUTE(0x001A7140);
g_sndBankRpcSend = ABSOLUTE(0x001A71C0);
g_sndBankRpcResult = ABSOLUTE(0x001A7180);
g_gameStateFlags = ABSOLUTE(0x001A7424);
sprintf = ABSOLUTE(0x00115DA8);
VfprintfDispatch = ABSOLUTE(0x00118CC8);
VfprintfInteger = ABSOLUTE(0x00119BF8);
VfprintfFloat = ABSOLUTE(0x00118D98);
IpuGetBits = ABSOLUTE(0x0012C878);
IpuSkipBits = ABSOLUTE(0x0012C788);
IpuWaitReady = ABSOLUTE(0x0012C3B0);
IpuWaitCmdResult = ABSOLUTE(0x0012C458);
IpuParseVideoStartCodes = ABSOLUTE(0x0012CAB0);
IpuParseGopHeader = ABSOLUTE(0x0012D060);
IpuDecodeSlice = ABSOLUTE(0x0012B8B0);
IpuWaitBdec = ABSOLUTE(0x0012B1C0);
IpuInitDecoder = ABSOLUTE(0x0012F738);
g_mcRpcRequest = ABSOLUTE(0x00141B80);
ResetEE = ABSOLUTE(0x0011A810);
SetGsCrt = ABSOLUTE(0x0011A820);
_LoadExecPS2 = ABSOLUTE(0x0011A860);
_ExecPS2 = ABSOLUTE(0x0011A870);
RFU009 = ABSOLUTE(0x0011A890);
AddSbusIntcHandler = ABSOLUTE(0x0011A8A0);
RemoveSbusIntcHandler = ABSOLUTE(0x0011A8B0);
Interrupt2Iop = ABSOLUTE(0x0011A8C0);
SetVTLBRefillHandler = ABSOLUTE(0x0011A8D0);
SetVCommonHandler = ABSOLUTE(0x0011A8E0);
SetVInterruptHandler = ABSOLUTE(0x0011A8F0);
RemoveIntcHandler = ABSOLUTE(0x0011A920);
RemoveDmacHandler = ABSOLUTE(0x0011A950);
_EnableIntc = ABSOLUTE(0x0011A960);
_DisableIntc = ABSOLUTE(0x0011A970);
_EnableDmac = ABSOLUTE(0x0011A980);
_DisableDmac = ABSOLUTE(0x0011A990);
_iEnableIntc = ABSOLUTE(0x0011A9C0);
_iDisableIntc = ABSOLUTE(0x0011A9D0);
_iEnableDmac = ABSOLUTE(0x0011A9E0);
_iDisableDmac = ABSOLUTE(0x0011A9F0);
iReleaseAlarm = ABSOLUTE(0x0011AA10);
DeleteThread = ABSOLUTE(0x0011AA30);
ExitThread = ABSOLUTE(0x0011AA50);
ExitDeleteThread = ABSOLUTE(0x0011AA60);
TerminateThread = ABSOLUTE(0x0011AA70);
iTerminateThread = ABSOLUTE(0x0011AA80);
DisableDispatchThread = ABSOLUTE(0x0011AA90);
EnableDispatchThread = ABSOLUTE(0x0011AAA0);
iChangeThreadPriority = ABSOLUTE(0x0011AAC0);
_iRotateThreadReadyQueue = ABSOLUTE(0x0011AAE0);
ReleaseWaitThread = ABSOLUTE(0x0011AAF0);
iReleaseWaitThread = ABSOLUTE(0x0011AB00);
ReferThreadStatus = ABSOLUTE(0x0011AB20);
iReferThreadStatus = ABSOLUTE(0x0011AB30);
_iWakeupThread = ABSOLUTE(0x0011AB60);
CancelWakeupThread = ABSOLUTE(0x0011AB70);
iCancelWakeupThread = ABSOLUTE(0x0011AB80);
_iSuspendThread = ABSOLUTE(0x0011ABA0);
ResumeThread = ABSOLUTE(0x0011ABB0);
iResumeThread = ABSOLUTE(0x0011ABC0);
RFU060 = ABSOLUTE(0x0011ABE0);
RFU061 = ABSOLUTE(0x0011ABF0);
EndOfHeap = ABSOLUTE(0x0011AC00);
SignalSema = ABSOLUTE(0x0011AC40);
PollSema = ABSOLUTE(0x0011AC70);
iPollSema = ABSOLUTE(0x0011AC80);
ReferSemaStatus = ABSOLUTE(0x0011AC90);
iReferSemaStatus = ABSOLUTE(0x0011ACA0);
GetGsHParam = ABSOLUTE(0x0011ACE0);
GetGsVParam = ABSOLUTE(0x0011ACF0);
SetGsHParam = ABSOLUTE(0x0011AD00);
SetGsVParam = ABSOLUTE(0x0011AD10);
iPutTLBEntry = ABSOLUTE(0x0011AD70);
GetTLBEntry = ABSOLUTE(0x0011AD90);
iProbeTLBEntry = ABSOLUTE(0x0011ADA0);
ExpandScratchPad = ABSOLUTE(0x0011ADB0);
EnableIntcHandler = ABSOLUTE(0x0011ADE0);
iEnableIntcHandler = ABSOLUTE(0x0011ADF0);
DisableIntcHandler = ABSOLUTE(0x0011AE00);
iDisableIntcHandler = ABSOLUTE(0x0011AE10);
EnableDmacHandler = ABSOLUTE(0x0011AE20);
iEnableDmacHandler = ABSOLUTE(0x0011AE30);
DisableDmacHandler = ABSOLUTE(0x0011AE40);
iDisableDmacHandler = ABSOLUTE(0x0011AE50);
KSeg0 = ABSOLUTE(0x0011AE60);
EnableCache = ABSOLUTE(0x0011AE70);
DisableCache = ABSOLUTE(0x0011AE80);
GetCop0 = ABSOLUTE(0x0011AE90);
CpuConfig = ABSOLUTE(0x0011AEB0);
iGetCop0 = ABSOLUTE(0x0011AEC0);
iFlushCache = ABSOLUTE(0x0011AED0);
iCpuConfig = ABSOLUTE(0x0011AEE0);
sceSifStopDma = ABSOLUTE(0x0011AEF0);
SetCPUTimerHandler = ABSOLUTE(0x0011AF00);
SetCPUTimer = ABSOLUTE(0x0011AF10);
SetOsdConfigParam2 = ABSOLUTE(0x0011AF20);
GetOsdConfigParam2 = ABSOLUTE(0x0011AF30);
GsGetIMR = ABSOLUTE(0x0011AF40);
iGsGetIMR = ABSOLUTE(0x0011AF50);
GsPutIMR = ABSOLUTE(0x0011AF60);
iGsPutIMR = ABSOLUTE(0x0011AF70);
SetPgifHandler = ABSOLUTE(0x0011AF80);
SetVSyncFlag = ABSOLUTE(0x0011AF90);
_print = ABSOLUTE(0x0011AFB0);
sceSifDmaStat = ABSOLUTE(0x0011AFC0);
isceSifDmaStat = ABSOLUTE(0x0011AFD0);
sceSifSetDma = ABSOLUTE(0x0011AFE0);
isceSifSetDma = ABSOLUTE(0x0011AFF0);
sceSifSetDChain = ABSOLUTE(0x0011B000);
isceSifSetDChain = ABSOLUTE(0x0011B010);
sceSifSetReg = ABSOLUTE(0x0011B020);
sceSifGetReg = ABSOLUTE(0x0011B030);
_ExecOSD = ABSOLUTE(0x0011B040);
PSMode = ABSOLUTE(0x0011B060);
MachineType = ABSOLUTE(0x0011B070);
_mbtowc_r = ABSOLUTE(0x00115FC0);
_free_r = ABSOLUTE(0x00116E10);
IntegerToAscii = ABSOLUTE(0x00118548);
BufferedWrite128 = ABSOLUTE(0x00118BC0);
BufferedWrite128Secondary = ABSOLUTE(0x00119AC0);
